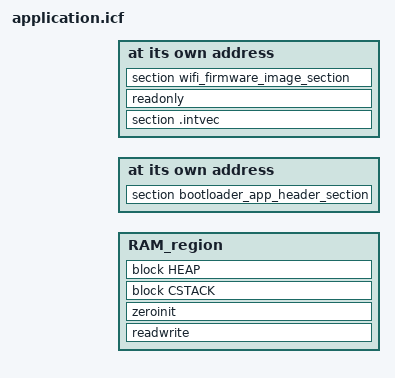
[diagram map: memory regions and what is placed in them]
/*
 * Copyright 2018, Cypress Semiconductor Corporation or a subsidiary of 
 * Cypress Semiconductor Corporation. All Rights Reserved.
 * 
 * This software, associated documentation and materials ("Software"),
 * is owned by Cypress Semiconductor Corporation
 * or one of its subsidiaries ("Cypress") and is protected by and subject to
 * worldwide patent protection (United States and foreign),
 * United States copyright laws and international treaty provisions.
 * Therefore, you may use this Software only as provided in the license
 * agreement accompanying the software package from which you
 * obtained this Software ("EULA").
 * If no EULA applies, Cypress hereby grants you a personal, non-exclusive,
 * non-transferable license to copy, modify, and compile the Software
 * source code solely for use in connection with Cypress's
 * integrated circuit products. Any reproduction, modification, translation,
 * compilation, or representation of this Software except as specified
 * above is prohibited without the express written permission of Cypress.
 *
 * Disclaimer: THIS SOFTWARE IS PROVIDED AS-IS, WITH NO WARRANTY OF ANY KIND,
 * EXPRESS OR IMPLIED, INCLUDING, BUT NOT LIMITED TO, NONINFRINGEMENT, IMPLIED
 * WARRANTIES OF MERCHANTABILITY AND FITNESS FOR A PARTICULAR PURPOSE. Cypress
 * reserves the right to make changes to the Software without notice. Cypress
 * does not assume any liability arising out of the application or use of the
 * Software or any product or circuit described in the Software. Cypress does
 * not authorize its products for use in any products where a malfunction or
 * failure of the Cypress product may reasonably be expected to result in
 * significant property damage, injury or death ("High Risk Product"). By
 * including Cypress's product in a High Risk Product, the manufacturer
 * of such system or application assumes all risk of such use and in doing
 * so agrees to indemnify Cypress against all liability.
 */
/* Define memory symbols */

/* Boot-loader vectors */
/* bootloader interrupt vectors start at 0x08000000 and ends at address 0x08000200 */
define symbol __Bootloader_vector_start           = 0x08000000;
define symbol __Bootloader_vector_length          = 512;
define symbol __AP_vector_length                = 512;
define symbol __Bootloader_vector_end             = (__Bootloader_vector_start + __Bootloader_vector_length);


/* Bootloader APIs */
/* starts at address 0x08000200 ends at address 0x08000400 */
define symbol __Bootloader_apis_start           = __Bootloader_vector_end;
define symbol __Bootloader_apis_length          = 512;
define symbol __Bootloader_apis_end                 = (__Bootloader_apis_start + __Bootloader_apis_length);


/* Bootloader code symbols */
/* starts at address 0x08000400 ends at address 0x08004000 */
define symbol __Bootloader_code_start            = __Bootloader_apis_end;
define symbol __Bootloader_code_length           = 0x3c00; /* 15 k */
define symbol __Bootloader_code_end                 = (__Bootloader_code_start + __Bootloader_code_length);


/* DCT1 symbols */
/* starts at address 0x08004000 ends at address 0x08008000 */
define symbol __DCT1_start                        = __Bootloader_code_end;
define symbol __DCT1_length                       = 0x4000; /* 16 k */
define symbol __DCT1_end                         = (__DCT1_start + __DCT1_length);


/* DCT2 symbols */
/* starts at address 0x08008000 ends at address 0x0800C000 */
define symbol __DCT2_start                        = __DCT1_end;
define symbol __DCT2_length                       = 0x4000; /* 16 k */
define symbol __DCT2_end                         = (__DCT2_start + __DCT2_length);


/* Application header symbols */
/* starts at address 0x0800C000 ends at address 0x0800C200  */
define symbol __App_header_start                    = __DCT2_end;
define symbol __App_header_length                   = 512;
define symbol __App_header_end                    = (__App_header_start + __App_header_length);


/* Application code symbols */
/* starts at address 0x0800C200 ends at address 0x08100200  */
define symbol __App_start                        = __App_header_end;
define symbol __App_length                       = 976k;
define symbol __App_end                            = (__App_start + __App_length);


/* SRAM memory location */
/* starts at address 0x20000000 ends at address 0x20020000 */
define symbol __SRAM_start                        = 0x20000000;
define symbol __SRAM_length                       = 128K;
define symbol __SRAM_end                        = (__SRAM_start + __SRAM_length);


/* Define memory regions */
define memory mem with size = 4G;
define region ROM_region   = mem:[from __Bootloader_vector_start   to __App_end];
define region RAM_region   = mem:[from __SRAM_start   to __SRAM_end];


/* create a stack block */
define block CSTACK    with alignment = 8, size = __STACKSIZE__   { };
/* create a heap block */
define block HEAP      with alignment = 8, size = 0x10000     { };

/* place application header */
place at address mem:__App_header_start   { section bootloader_app_header_section };

keep {section bootloader_app_header_section};

/* place application and its data */
place at address mem:(__App_start ) { section .intvec, readonly, section wifi_firmware_image_section };

initialize by copy { readwrite };


place in RAM_region   { readwrite,
                        zeroinit,
                        block CSTACK,
                        block HEAP,
                      };

/* export symbols */
define symbol bootloader_api_addr_loc = __Bootloader_apis_start;
export symbol bootloader_api_addr_loc;

/* vectors offset */
define symbol vectors_offset = __App_start -  __App_header_start;
export symbol vectors_offset;

define symbol app_hdr_start_addr_loc = __App_header_start;
export symbol app_hdr_start_addr_loc;
